# LPC13Uxx register map
File version: 1
CPU: CM3 r2p1, little endian, no MPU, no FPU, 3 interrupt priority bits
Registers are 32-bit, read-write, reset 0x0 unless marked. A register's access mark holds for its fields unless they carry their own. Offsets are from the block's base; [hi:lo] are bit positions; {n}, {i} and the like mark numbered series.

## CT16B0 — 16-bit counter/timers CT16B0
Base 0x4000C000
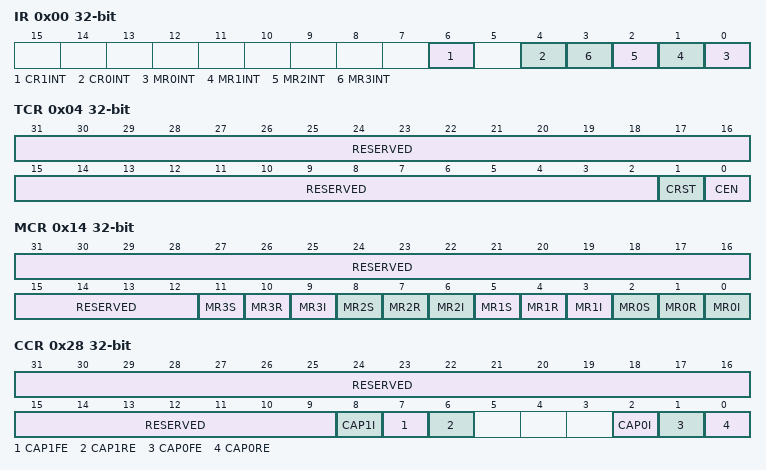
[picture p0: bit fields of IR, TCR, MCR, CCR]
0x00 IR — Interrupt Register. The IR can be written to clear interrupts. The IR can be read to identify which of eight possible interrupt sources are pending.
  [6] CR1INT — Interrupt flag for capture channel 1 event.
  [4] CR0INT — Interrupt flag for capture channel 0 event.
  [n] MR{n}INT (n=0..3) — Interrupt flag for match channel {n}.
0x04 TCR — Timer Control Register. The TCR is used to control the Timer Counter functions. The Timer Counter can be disabled or reset through the TCR.
  [31:2] RESERVED — Reserved, user software should not write ones to reserved bits. The value read from a reserved bit is not defined.
  [1] CRST — Counter reset.
    0=DO_NOTHING_; 1=THE_TIMER_COUNTER_AN (The Timer Counter and the Prescale Counter are synchronously reset on the next positive edge of PCLK. The counters remain reset until TCR\[1\] is returned to zero.)
  [0] CEN — Counter enable.
    0=THE_COUNTERS_ARE_DIS (The counters are disabled.); 1=THE_TIMER_COUNTER_AN (The Timer Counter and Prescale Counter are enabled for counting.)
0x08 TC — Timer Counter. The 16-bit TC is incremented every PR+1 cycles of PCLK. The TC is controlled through the TCR.
  [15:0] TC — Timer counter value.
0x0C PR — Prescale Register. When the Prescale Counter (below) is equal to this value, the next clock increments the TC and clears the PC.
  [15:0] PCVAL — Prescale value.
0x10 PC — Prescale Counter. The 16-bit PC is a counter which is incremented to the value stored in PR. When the value in PR is reached, the TC is incremented and the PC is cleared. The PC is observable and controllable through the bus interface.
  [15:0] PC — Prescale counter value.
0x14 MCR — Match Control Register. The MCR is used to control if an interrupt is generated and if the TC is reset when a Match occurs.
  [31:12] RESERVED — Reserved, user software should not write ones to reserved bits. The value read from a reserved bit is not defined.
  [3n+2] MR{n}S (n=0..3) — Stop on MR{n}: the TC and PC will be stopped and TCR\[0\] will be set to 0 if MR{n} matches the TC.
    1=ENABLED; 0=DISABLED
  [3n+1] MR{n}R (n=0..3) — Reset on MR{n}: the TC will be reset if MR{n} matches it.
    1=ENABLED; 0=DISABLED
  [3n] MR{n}I (n=0..3) — Interrupt on MR{n}: an interrupt is generated when MR{n} matches the value in the TC.
    1=ENABLED; 0=DISABLED
{0x18+4i} MR{i} (i=0..3) — Match Register 0. MR0 can be enabled through the MCR to reset the TC, stop both the TC and PC, and/or generate an interrupt every time MR0 matches the TC.
  [15:0] MATCH — Timer counter match value.
0x28 CCR — Capture Control Register. The CCR controls which edges of the capture inputs are used to load the Capture Registers and whether or not an interrupt is generated when a capture takes place.
  [31:9] RESERVED — Reserved, user software should not write ones to reserved bits. The value read from a reserved bit is not defined.
  [8] CAP1I — Interrupt on CT16B0_CAP1 event: a CR1 load due to a CT16B0_CAP1 event will generate an interrupt. This bit is reserved for 16-bit timer1 CT16B1.
    1=ENABLED_; 0=DISABLED_
  [7] CAP1FE — Capture on CT16B0_CAP1 falling edge: a sequence of 1 then 0 on CT16B0_CAP1 will cause CR1 to be loaded with the contents of TC. This bit is reserved for 16-bit timer1 CT16B1.
    1=ENABLED_; 0=DISABLED_
  [6] CAP1RE — Capture on CT16B0_CAP1 rising edge: a sequence of 0 then 1 on CT16B0_CAP1 will cause CR1 to be loaded with the contents of TC. This bit is reserved for 16-bit timer1 CT16B1.
    1=ENABLED_; 0=DISABLED_
  [2] CAP0I — Interrupt on CT16B0_CAP0 event: a CR0 load due to a CT16B0_CAP0 event will generate an interrupt.
    1=ENABLED_; 0=DISABLED_
  [1] CAP0FE — Capture on CT16B0_CAP0 falling edge: a sequence of 1 then 0 on CT16B0_CAP0 will cause CR0 to be loaded with the contents of TC.
    1=ENABLED_; 0=DISABLED_
  [0] CAP0RE — Capture on CT16B0_CAP0 rising edge: a sequence of 0 then 1 on CT16B0_CAP0 will cause CR0 to be loaded with the contents of TC.
    1=ENABLED_; 0=DISABLED_
0x2C CR0 ro — Capture Register 0. CR0 is loaded with the value of TC when there is an event on the CT16B0_CAP0 input.
  [15:0] CAP — Timer counter capture value.
0x34 CR1 ro reset not defined — Capture Register 1. CR1 is loaded with the value of TC when there is an event on the CT16B0_CAP1 input.
  [15:0] CAP — Timer counter capture value.
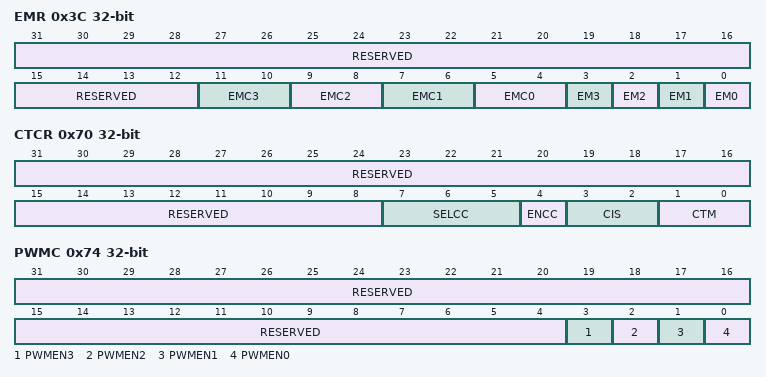
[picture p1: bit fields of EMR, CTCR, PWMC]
0x3C EMR — External Match Register. The EMR controls the match function and the external match pins CT16B0_MAT\[1:0\] and CT16B1_MAT\[1:0\].
  [31:12] RESERVED — Reserved, user software should not write ones to reserved bits. The value read from a reserved bit is not defined.
  [11:10] EMC3 — External Match Control 3. Determines the functionality of External Match 3.
    0=DO_NOTHING_; 1=CLEAR_THE_CORRESPOND (Clear the corresponding External Match bit/output to 0 (CT16Bn_MAT3 pin is LOW if pinned out).); 2=SET_THE_CORRESPONDIN (Set the corresponding External Match bit/output to 1 (CT16Bn_MAT3 pin is HIGH if pinned out).); 3=TOGGLE_THE_CORRESPON (Toggle the corresponding External Match bit/output.)
  [9:8] EMC2 — External Match Control 2. Determines the functionality of External Match 2.
    0=DO_NOTHING_; 1=CLEAR_THE_CORRESPOND (Clear the corresponding External Match bit/output to 0 (CT16Bn_MAT2 pin is LOW if pinned out).); 2=SET_THE_CORRESPONDIN (Set the corresponding External Match bit/output to 1 (CT16Bn_MAT2 pin is HIGH if pinned out).); 3=TOGGLE_THE_CORRESPON (Toggle the corresponding External Match bit/output.)
  [7:6] EMC1 — External Match Control 1. Determines the functionality of External Match 1.
    0=DO_NOTHING_; 1=CLEAR_THE_CORRESPOND (Clear the corresponding External Match bit/output to 0 (CT16Bn_MAT1 pin is LOW if pinned out).); 2=SET_THE_CORRESPONDIN (Set the corresponding External Match bit/output to 1 (CT16Bn_MAT1 pin is HIGH if pinned out).); 3=TOGGLE_THE_CORRESPON (Toggle the corresponding External Match bit/output.)
  [5:4] EMC0 — External Match Control 0. Determines the functionality of External Match 0. Table 296 shows the encoding of these bits.
    0=DO_NOTHING_; 1=CLEAR_THE_CORRESPOND (Clear the corresponding External Match bit/output to 0 (CT16Bn_MAT0 pin is LOW if pinned out).); 2=SET_THE_CORRESPONDIN (Set the corresponding External Match bit/output to 1 (CT16Bn_MAT0 pin is HIGH if pinned out).); 3=TOGGLE_THE_CORRESPON (Toggle the corresponding External Match bit/output.)
  [3] EM3 — External Match 3. This bit reflects the state of output of match channel 3. When a match occurs between the TC and MR3, this bit can either toggle, go LOW, go HIGH, or do nothing. Bits EMR\[11:10\] control the functionality of this output.
  [2] EM2 — External Match 2. This bit reflects the state of match channel 2. When a match occurs between the TC and MR2, this bit can either toggle, go LOW, go HIGH, or do nothing. Bits EMR\[9:8\] control the functionality of this output.
  [1] EM1 — External Match 1. This bit reflects the state of output CT16B0_MAT1/CT16B1_MAT1, whether or not this output is connected to its pin. When a match occurs between the TC and MR1, this bit can either toggle, go LOW, go HIGH, or do nothing. Bits EMR\[7:6\] control the functionality of this output. This bit is driven to the CT16B0_MAT0/CT16B1_MAT0 pins if the match function is selected in the IOCON registers (0 = LOW, 1 = HIGH).
  [0] EM0 — External Match 0. This bit reflects the state of output CT16B0_MAT0/CT16B1_MAT0, whether or not this output is connected to its pin. When a match occurs between the TC and MR0, this bit can either toggle, go LOW, go HIGH, or do nothing. Bits EMR\[5:4\] control the functionality of this output. This bit is driven to the CT16B0_MAT0/CT16B1_MAT0 pins if the match function is selected in the IOCON registers (0 = LOW, 1 = HIGH).
0x70 CTCR — Count Control Register. The CTCR selects between Timer and Counter mode, and in Counter mode selects the signal and edge(s) for counting.
  [31:8] RESERVED — Reserved, user software should not write ones to reserved bits. The value read from a reserved bit is not defined.
  [7:5] SELCC — Edge select. When bit 4 is 1, these bits select which capture input edge will cause the timer and prescaler to be cleared. These bits have no effect when bit 4 is low. Values 0x2 to 0x3 and 0x6 to 0x7 are reserved.
    0=RISING_EDGE_OF_CT16B0_CAP0 (Rising Edge of CT16B0_CAP0 clears the timer (if bit 4 is set).); 1=FALLING_EDGE_OF_CT16B0_CAP0 (Falling Edge of CT16B0_CCAP0 clears the timer (if bit 4 is set).); 4=RISING_EDGE_OF_CT16B0_CAP1 (Rising Edge of CT16B0_CAP1 clears the timer (if bit 4 is set).); 5=FALLING_EDGE_OF_CT160_CAP1 (Falling Edge of CT16B0_CAP1 clears the timer (if bit 4 is set).)
  [4] ENCC — Setting this bit to 1 enables clearing of the timer and the prescaler when the capture-edge event specified in bits 7:5 occurs.
  [3:2] CIS — Count Input Select. In counter mode (when bits 1:0 in this register are not 00), these bits select which CAP pin or comparator output is sampled for clocking. Values 0x1 and 0x3 are reserved.
    0=CT16B0_CAP0_; 2=CT16B0_CAP1_
  [1:0] CTM — Counter/Timer Mode. This field selects which rising PCLK edges can increment Timer's Prescale Counter (PC), or clear PC and increment Timer Counter (TC). If Counter mode is selected in the CTCR, bits 2:0 in the Capture Control Register (CCR) must be programmed as 000.
    0=TIMER_MODE_EVERY_RISING (Timer Mode: every rising PCLK edge); 1=COUNTER_MODE_TC_IS_RISING (Counter Mode: TC is incremented on rising edges on the CAP input selected by bits 3:2.); 2=COUNTER_MODE_TC_IS_FALLING (Counter Mode: TC is incremented on falling edges on the CAP input selected by bits 3:2.); 3=COUNTER_MODE_TC_IS_BOTH (Counter Mode: TC is incremented on both edges on the CAP input selected by bits 3:2.)
0x74 PWMC — PWM Control Register. The PWMCON enables PWM mode for the external match pins CT16B0_MAT\[1:0\] and CT16B1_MAT\[1:0\].
  [31:4] RESERVED — Reserved, user software should not write ones to reserved bits. The value read from a reserved bit is not defined.
  [3] PWMEN3 — PWM mode enable for channel3.
    0=CT16BN_MAT3_IS_CONTR (CT16Bn_MAT3 is controlled by EM3.); 1=PWM_MODE_IS_ENABLED_ (PWM mode is enabled for CT16Bn_MAT3.)
  [2] PWMEN2 — PWM mode enable for channel2.
    0=CT16BN_MAT2_IS_CONTR (CT16Bn_MAT2 is controlled by EM2.); 1=PWM_MODE_IS_ENABLED_ (PWM mode is enabled for CT16Bn_MAT2.)
  [1] PWMEN1 — PWM mode enable for channel1.
    0=CT16BN_MAT01_IS_CONT (CT16Bn_MAT01 is controlled by EM1.); 1=PWM_MODE_IS_ENABLED_ (PWM mode is enabled for CT16Bn_MAT1.)
  [0] PWMEN0 — PWM mode enable for channel0.
    0=CT16BN_MAT0_IS_CONTR (CT16Bn_MAT0 is controlled by EM0.); 1=PWM_MODE_IS_ENABLED_ (PWM mode is enabled for CT16Bn_MAT0.)
